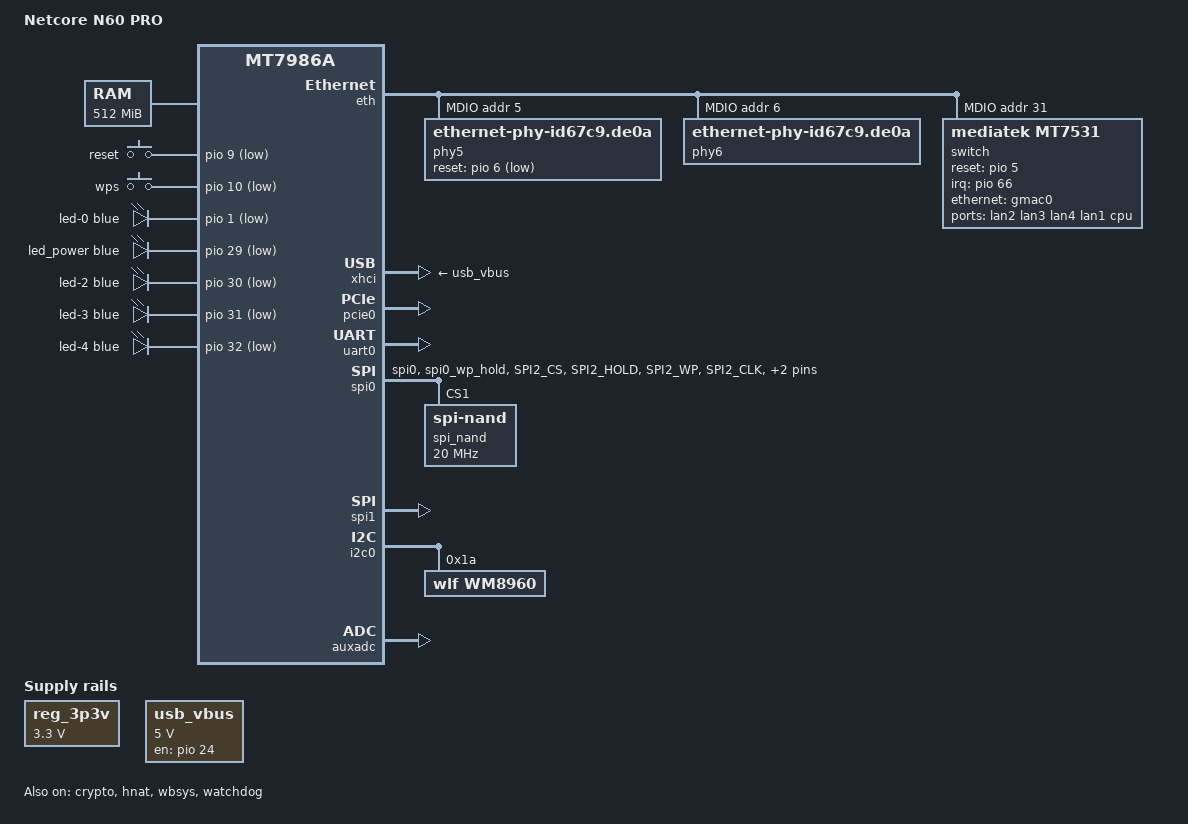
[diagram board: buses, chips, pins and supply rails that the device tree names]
// SPDX-License-Identifier: (GPL-2.0-only OR MIT)
/dts-v1/;

#include <dt-bindings/input/input.h>
#include <dt-bindings/gpio/gpio.h>
#include <dt-bindings/leds/common.h>

#include "mt7986a.dtsi"
#include "mt7986a-pinctrl.dtsi"
/ {
	model = "Netcore N60 PRO";
	compatible = "netcore,n60-pro", "mediatek,mt7986a";
	chosen {
		bootargs = "console=ttyS0,115200n1 loglevel=8  \
		earlycon=uart8250,mmio32,0x11002000";
	};

	aliases {
		led-boot = &led_power;
 		led-failsafe = &led_power;
 		led-running = &led_power;
 		led-upgrade = &led_power;
	};

	memory {
		reg = <0 0x40000000 0 0x20000000>;
	};

	gpio-keys {
		compatible = "gpio-keys";

		button-reset {
			label = "reset";
			linux,code = <KEY_RESTART>;
			gpios = <&pio 9 GPIO_ACTIVE_LOW>;
		};

		button-wps {
			label = "wps";
			linux,code = <KEY_WPS_BUTTON>;
			gpios = <&pio 10 GPIO_ACTIVE_LOW>;
		};
	};

	leds {
		compatible = "gpio-leds";

		led-0 {
 			color = <LED_COLOR_ID_BLUE>;
 			function = LED_FUNCTION_WLAN;
 			gpios = <&pio 1 GPIO_ACTIVE_LOW>;
 			linux,default-trigger = "phy1tpt";
 		};
 
 		led_power: led-1 {
 			color = <LED_COLOR_ID_BLUE>;
 			function = LED_FUNCTION_POWER;
 			gpios = <&pio 29 GPIO_ACTIVE_LOW>;
 		};
 
 		led-2 {
 			color = <LED_COLOR_ID_BLUE>;
 			function = LED_FUNCTION_USB;
 			gpios = <&pio 30 GPIO_ACTIVE_LOW>;
 		};
 
 		led-3 {
 			color = <LED_COLOR_ID_BLUE>;
 			function = LED_FUNCTION_WPS;
 			gpios = <&pio 31 GPIO_ACTIVE_LOW>;
 		};
 
 		led-4 {
 			color = <LED_COLOR_ID_BLUE>;
 			function = LED_FUNCTION_WAN;
 			gpios = <&pio 32 GPIO_ACTIVE_LOW>;
 		};
	};

	nmbm_spim_nand {
		compatible = "generic,nmbm";

		#address-cells = <1>;
		#size-cells = <1>;

		lower-mtd-device = <&spi_nand>;
		forced-create;

		partitions {
			compatible = "fixed-partitions";
			#address-cells = <1>;
			#size-cells = <1>;

			partition@0 {
				label = "BL2";
				reg = <0x00000 0x0100000>;
				read-only;
			};

			partition@100000 {
				label = "u-boot-env";
				reg = <0x0100000 0x0080000>;
			};

			Factory: partition@180000 {
				label = "Factory";
				reg = <0x180000 0x0200000>;
			};

			partition@380000 {
				label = "FIP";
				reg = <0x380000 0x0200000>;
			};

			partition@580000 {
				label = "ubi";
				reg = <0x580000 0x7280000>;
			};
		};
	};

	reg_3p3v: regulator-3p3v {
		compatible = "regulator-fixed";
		regulator-name = "fixed-3.3V";
		regulator-min-microvolt = <3300000>;
		regulator-max-microvolt = <3300000>;
		regulator-boot-on;
		regulator-always-on;
	};

	usb_vbus: regulator-usb-vbus {
		compatible = "regulator-fixed";
		regulator-name = "usb_vbus";
		regulator-min-microvolt = <5000000>;
		regulator-max-microvolt = <5000000>;
		gpios = <&pio 24 GPIO_ACTIVE_HIGH>;
		enable-active-high;
		regulator-boot-on;
	};
};


&crypto {
	status = "okay";
};

&eth {
	status = "okay";

	gmac0: mac@0 {
		compatible = "mediatek,eth-mac";
		reg = <0>;
		phy-mode = "2500base-x";
		fixed-link {
			speed = <2500>;
			full-duplex;
			pause;
		};
	};

	gmac1: mac@1 {
		compatible = "mediatek,eth-mac";
		reg = <1>;
		label = "wan";
		phy-mode = "2500base-x";

		fixed-link {
			speed = <2500>;
			full-duplex;
			pause;
		};
	};

	mdio: mdio-bus {
		#address-cells = <1>;
		#size-cells = <0>;
	};
};

&mdio {
	phy5: phy@5 {
		compatible = "ethernet-phy-id67c9.de0a";
		reg = <5>;
		reset-gpios = <&pio 6 GPIO_ACTIVE_LOW>;
		reset-assert-us = <50000>;
		reset-deassert-us = <20000>;
		mxl,led-config = <0x0 0x0 0x0 0x3f0>;
	};

	phy6: phy@6 {
		compatible = "ethernet-phy-id67c9.de0a";
		reg = <6>;
		mxl,led-config = <0x0 0x0 0x0 0x3f0>;
	};

	switch: switch@0 {
		compatible = "mediatek,mt7531";
		reg = <31>;
		reset-gpios = <&pio 5 GPIO_ACTIVE_HIGH>;
		interrupt-controller;
		#interrupt-cells = <1>;
		interrupt-parent = <&pio>;
		interrupts = <66 IRQ_TYPE_LEVEL_HIGH>;
	};
};

&switch {
	ports {
		#address-cells = <1>;
		#size-cells = <0>;

		port@1 {
			reg = <0>;
			label = "lan2";
		};

		port@3 {
			reg = <3>;
			label = "lan3";
		};

		port@4 {
			reg = <4>;
			label = "lan4";
		};

		port@5 {
			reg = <5>;
			label = "lan1";
			phy-mode = "2500base-x";
			fixed-link {
				speed = <2500>;
				full-duplex;
				pause;
			};
		};

		port@6 {
			reg = <6>;
			label = "cpu";
			ethernet = <&gmac0>;
			phy-mode = "2500base-x";

			fixed-link {
				speed = <2500>;
				full-duplex;
				pause;
			};
		};
	};
};

&xhci {
	vusb33-supply = <&reg_3p3v>;
	vbus-supply = <&usb_vbus>;
	status = "okay";
};

&hnat {
	mtketh-wan = "eth1";
	mtketh-lan = "lan";
	mtketh-max-gmac = <2>;
	status = "okay";
};

&pio {
	spi_flash_pins: spi-flash-pins-33-to-38 {
		mux {
			function = "flash";
			groups = "spi0", "spi0_wp_hold";
		};
		conf-pu {
			pins = "SPI2_CS", "SPI2_HOLD", "SPI2_WP";
			drive-strength = <8>;
			mediatek,pull-up-adv = <0>;
		};
		conf-pd {
			pins = "SPI2_CLK", "SPI2_MOSI", "SPI2_MISO";
			drive-strength = <8>;
			mediatek,pull-down-adv = <0>;
		};
	};

	wf_2g_5g_pins: wf_2g_5g-pins {
		mux {
			function = "wifi";
			groups = "wf_2g", "wf_5g";
		};
		conf {
			pins = "WF0_HB1", "WF0_HB2", "WF0_HB3", "WF0_HB4",
			"WF0_HB0", "WF0_HB0_B", "WF0_HB5", "WF0_HB6",
			"WF0_HB7", "WF0_HB8", "WF0_HB9", "WF0_HB10",
			"WF0_TOP_CLK", "WF0_TOP_DATA", "WF1_HB1",
			"WF1_HB2", "WF1_HB3", "WF1_HB4", "WF1_HB0",
			"WF1_HB5", "WF1_HB6", "WF1_HB7", "WF1_HB8",
			"WF1_TOP_CLK", "WF1_TOP_DATA";
			drive-strength = <MTK_DRIVE_4mA>;
		};
	};

	wf_dbdc_pins: wf_dbdc-pins {
		mux {
			function = "wifi";
			groups = "wf_dbdc";
		};
		conf {
			pins = "WF0_HB1", "WF0_HB2", "WF0_HB3", "WF0_HB4",
			"WF0_HB0", "WF0_HB0_B", "WF0_HB5", "WF0_HB6",
			"WF0_HB7", "WF0_HB8", "WF0_HB9", "WF0_HB10",
			"WF0_TOP_CLK", "WF0_TOP_DATA", "WF1_HB1",
			"WF1_HB2", "WF1_HB3", "WF1_HB4", "WF1_HB0",
			"WF1_HB5", "WF1_HB6", "WF1_HB7", "WF1_HB8",
			"WF1_TOP_CLK", "WF1_TOP_DATA";
			drive-strength = <MTK_DRIVE_4mA>;
		};
	};
};

&pcie0 {
	pinctrl-names = "default";
	pinctrl-0 = <&pcie0_pins>;
	status = "okay";
};

&uart0 {
	status = "okay";
};

&spi0 {
	pinctrl-names = "default";
	pinctrl-0 = <&spi_flash_pins>;
	status = "okay";
	cs-gpios = <0>, <0>;
	spi_nand: spi_nand@0 {
		#address-cells = <1>;
		#size-cells = <1>;
		compatible = "spi-nand";
		reg = <1>;
		spi-max-frequency = <20000000>;
		spi-tx-buswidth = <4>;
		spi-rx-buswidth = <4>;
	};
};

&wbsys {
	status = "okay";
	mediatek,mtd-eeprom = <&Factory 0x0000>;
};

&spi1 {
	pinctrl-names = "default";
	pinctrl-0 = <&spic_pins_g1>;
	status = "okay";
};


&watchdog {
	status = "okay";
};

&i2c0 {
	pinctrl-names = "default";
	pinctrl-0 = <&i2c_pins>;
	status = "okay";

	wm8960: wm8960@1a {
		compatible = "wlf,wm8960";
		reg = <0x1a>;
	};
};

&auxadc {
	status = "okay";
};
